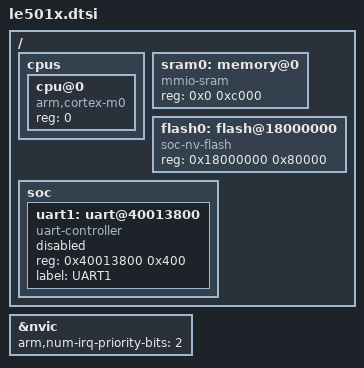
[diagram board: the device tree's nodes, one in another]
#include <arm/armv6-m.dtsi>

/ {
    cpus {
		#address-cells = <1>;
		#size-cells = <0>;

		cpu@0 {
			device_type = "cpu";
			compatible = "arm,cortex-m0";
			reg = <0>;
		};
    };
    sram0: memory@0 {
        compatible = "mmio-sram";
        reg = <0x0 0xc000>;
    };
    flash0: flash@18000000 {
        compatible = "soc-nv-flash";
        reg = <0x18000000 0x80000>;
    };
    soc {
        uart1: uart@40013800 {
            compatible = "uart-controller";
            reg = <0x40013800 0x400>;
			status = "disabled";
            label = "UART1";
        };
    };
};

&nvic {
	arm,num-irq-priority-bits = <2>;
};
